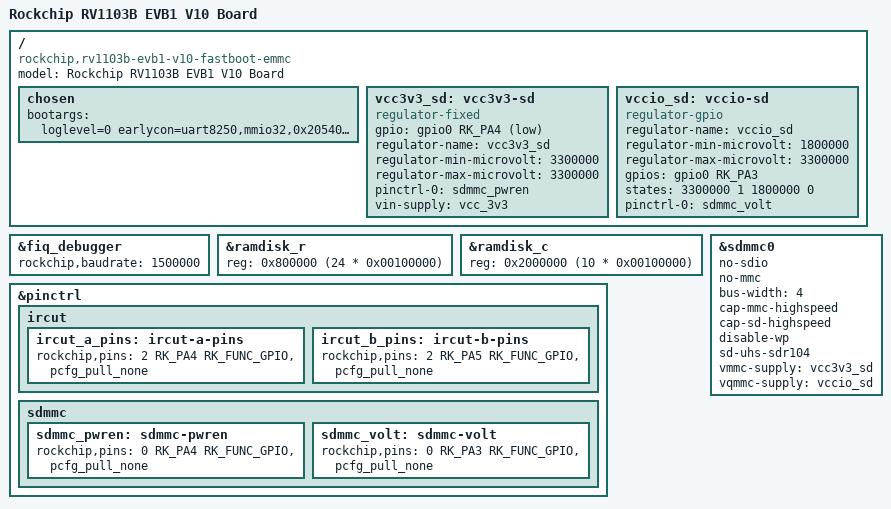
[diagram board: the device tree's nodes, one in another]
// SPDX-License-Identifier: (GPL-2.0+ OR MIT)
/*
 * Copyright (c) 2026 Rockchip Electronics Co., Ltd.
 */

/dts-v1/;

#include "rv1103b.dtsi"
#include "rv1103b-evb.dtsi"
#include "rv1103b-evb-cam.dtsi"
#include "rv1106b-fastboot-emmc.dtsi"

/ {
	model = "Rockchip RV1103B EVB1 V10 Board";
	compatible = "rockchip,rv1103b-evb1-v10-fastboot-emmc", "rockchip,rv1103b";

	chosen {
		bootargs = "loglevel=0 earlycon=uart8250,mmio32,0x20540000 console=ttyFIQ0 root=/dev/rd0 rootfstype=erofs rootflags=dax snd_soc_core.prealloc_buffer_size_kbytes=16 coherent_pool=32K";
	};

	vcc3v3_sd: vcc3v3-sd {
		compatible = "regulator-fixed";
		gpio = <&gpio0 RK_PA4 GPIO_ACTIVE_LOW>;
		regulator-name = "vcc3v3_sd";
		regulator-min-microvolt = <3300000>;
		regulator-max-microvolt = <3300000>;
		pinctrl-names = "default";
		pinctrl-0 = <&sdmmc_pwren>;
		vin-supply = <&vcc_3v3>;
	};

	vccio_sd: vccio-sd {
		compatible = "regulator-gpio";
		regulator-name = "vccio_sd";
		regulator-min-microvolt = <1800000>;
		regulator-max-microvolt = <3300000>;
		gpios = <&gpio0 RK_PA3 GPIO_ACTIVE_HIGH>;
		states = <3300000 1
			  1800000 0>;
		pinctrl-names = "default";
		pinctrl-0 = <&sdmmc_volt>;
	};
};

&fiq_debugger {
	rockchip,baudrate = <1500000>;  /* Only 115200 and 1500000 */
};

&ramdisk_r {
	reg = <0x800000 (24 * 0x00100000)>;
};

&ramdisk_c {
	reg = <0x2000000 (10 * 0x00100000)>;
};

&sdmmc0 {
	no-sdio;
	no-mmc;
	bus-width = <4>;
	cap-mmc-highspeed;
	cap-sd-highspeed;
	disable-wp;
	sd-uhs-sdr104;
	vmmc-supply = <&vcc3v3_sd>;
	vqmmc-supply = <&vccio_sd>;
	status = "okay";
};

&pinctrl {
	ircut {
		ircut_a_pins: ircut-a-pins {
			rockchip,pins = <2 RK_PA4 RK_FUNC_GPIO &pcfg_pull_none>;
		};

		ircut_b_pins: ircut-b-pins {
			rockchip,pins = <2 RK_PA5 RK_FUNC_GPIO &pcfg_pull_none>;
		};
	};

	sdmmc {
		/omit-if-no-ref/
		sdmmc_pwren: sdmmc-pwren {
			rockchip,pins = <0 RK_PA4 RK_FUNC_GPIO &pcfg_pull_none>;
		};

		/omit-if-no-ref/
		sdmmc_volt: sdmmc-volt {
			rockchip,pins = <0 RK_PA3 RK_FUNC_GPIO &pcfg_pull_none>;
		};
	};
};
